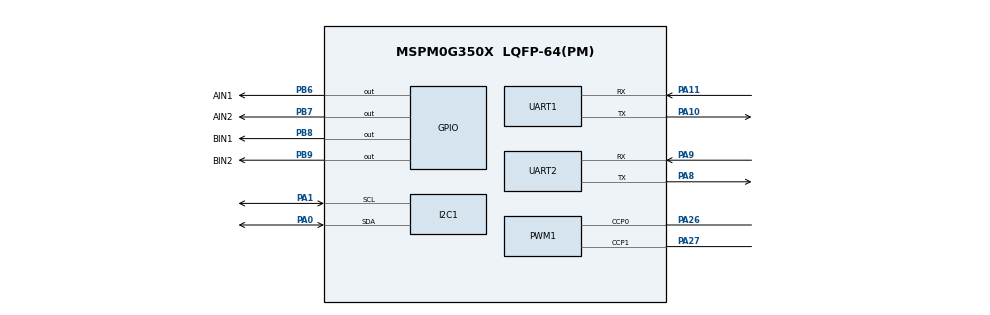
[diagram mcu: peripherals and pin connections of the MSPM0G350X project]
/**
 * @cliArgs --device "MSPM0G350X" --part "Default" --package "LQFP-64(PM)" --product "mspm0_sdk@2.05.01.01"
 * @versions {"tool":"1.24.0+4110"}
 */

/**
 * Import the modules used in this configuration.
 */
const GPIO   = scripting.addModule("/ti/driverlib/GPIO", {}, false);
const GPIO1  = GPIO.addInstance();
const SYSCTL = scripting.addModule("/ti/driverlib/SYSCTL");
const UART   = scripting.addModule("/ti/driverlib/UART", {}, false);
const UART1  = UART.addInstance();
const UART2  = UART.addInstance();
const I2C    = scripting.addModule("/ti/driverlib/I2C", {}, false);
const I2C1   = I2C.addInstance();
const TIMER  = scripting.addModule("/ti/driverlib/TIMER", {}, false);
const TIMER1 = TIMER.addInstance();
const PWM    = scripting.addModule("/ti/driverlib/PWM", {}, false);
const PWM1   = PWM.addInstance();

/**
 * Write custom configuration values to the imported modules.
 */
SYSCTL.forceDefaultClkConfig = true;

const Board = scripting.addModule("/ti/driverlib/Board", {}, false);
GPIO1.$name                         = "MOTOR_DIR";
GPIO1.port                          = "PORTB";
GPIO1.associatedPins.create(4);
GPIO1.associatedPins[0].$name       = "AIN1";
GPIO1.associatedPins[0].pin.$assign = "PB6";
GPIO1.associatedPins[1].$name       = "AIN2";
GPIO1.associatedPins[1].pin.$assign = "PB7";
GPIO1.associatedPins[2].$name       = "BIN1";
GPIO1.associatedPins[2].pin.$assign = "PB8";
GPIO1.associatedPins[3].$name       = "BIN2";
GPIO1.associatedPins[3].pin.$assign = "PB9";

UART1.$name                    = "UART_0";
UART1.targetBaudRate           = 115200;
UART1.peripheral.rxPin.$assign = "PA11";
UART1.peripheral.txPin.$assign = "PA10";
UART1.txPinConfig.$name        = "ti_driverlib_gpio_GPIOPinGeneric0";
UART1.rxPinConfig.$name        = "ti_driverlib_gpio_GPIOPinGeneric1";

UART2.$name                    = "BT_UART";
UART2.targetBaudRate           = 9600;
UART2.peripheral.$assign       = "UART1";
UART2.peripheral.txPin.$assign = "PA8";
UART2.peripheral.rxPin.$assign = "PA9";
UART2.txPinConfig.$name        = "ti_driverlib_gpio_GPIOPinGeneric4";
UART2.rxPinConfig.$name        = "ti_driverlib_gpio_GPIOPinGeneric5";

I2C1.basicEnableController             = true;
I2C1.basicControllerBusSpeed           = 100000;
I2C1.$name                             = "I2C_0";
I2C1.advAnalogGlitchFilter             = "DISABLED";
I2C1.peripheral.$assign                = "I2C0";
I2C1.peripheral.sclPin.$assign         = "PA1";
I2C1.peripheral.sdaPin.$assign         = "PA0";
I2C1.sclPinConfig.$name                = "ti_driverlib_gpio_GPIOPinGeneric2";
I2C1.sclPinConfig.hideOutputInversion  = scripting.forceWrite(false);
I2C1.sclPinConfig.onlyInternalResistor = scripting.forceWrite(false);
I2C1.sclPinConfig.passedPeripheralType = scripting.forceWrite("Digital");
I2C1.sdaPinConfig.$name                = "ti_driverlib_gpio_GPIOPinGeneric3";
I2C1.sdaPinConfig.hideOutputInversion  = scripting.forceWrite(false);
I2C1.sdaPinConfig.onlyInternalResistor = scripting.forceWrite(false);
I2C1.sdaPinConfig.passedPeripheralType = scripting.forceWrite("Digital");
TIMER1.$name              = "TIMER_0";
TIMER1.timerClkDiv        = 8;
TIMER1.timerClkPrescale   = 100;
TIMER1.timerMode          = "PERIODIC";
TIMER1.timerPeriod        = "50 ms";
TIMER1.timerStartTimer    = true;
TIMER1.interrupts         = ["ZERO"];
TIMER1.peripheral.$assign = "TIMG0";
PWM1.$name           = "MOTOR_PWM";
PWM1.clockDivider    = 8;
PWM1.timerStartTimer = true;
PWM1.ccIndex         = [0, 1];
PWM1.pwmMode         = "EDGE_ALIGN_UP";
PWM1.peripheral.$assign = "TIMG8";
PWM1.peripheral.ccp0Pin.$assign = "PA26";
PWM1.peripheral.ccp1Pin.$assign = "PA27";
PWM1.PWM_CHANNEL_0.$name = "ti_driverlib_pwm_PWMTimerCC0";
PWM1.PWM_CHANNEL_1.$name = "ti_driverlib_pwm_PWMTimerCC1";

/**
 * Pinmux solution for unlocked pins/peripherals. This ensures that minor changes to the automatic solver in a future
 * version of the tool will not impact the pinmux you originally saw.  These lines can be completely deleted in order to
 * re-solve from scratch.
 */
SYSCTL.peripheral.$suggestSolution         = "SYSCTL";
Board.peripheral.$suggestSolution          = "DEBUGSS";
Board.peripheral.swclkPin.$suggestSolution = "PA20";
Board.peripheral.swdioPin.$suggestSolution = "PA19";
UART1.peripheral.$suggestSolution          = "UART0";
UART2.peripheral.$suggestSolution          = "UART1";
